# TMS320F280049 register map
Vendor: Texas Instruments; Series: C2000 F28004x; File version: 0.2.0-generated
Registers are 16-bit, read-write, reset 0x0 unless marked. A register's access mark holds for its fields unless they carry their own. Offsets are from the block's base; [hi:lo] are bit positions; {n}, {i} and the like mark numbered series.

## OUTPUTXBARREGS — OUTPUT XBAR Registers
Base 0x0000F500
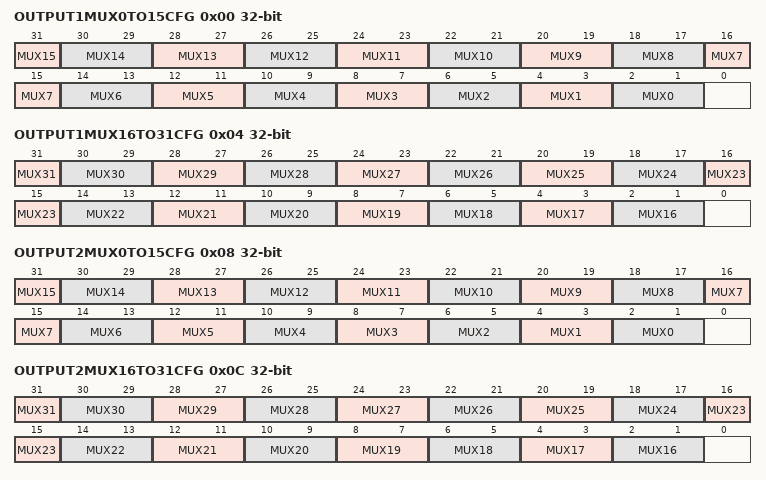
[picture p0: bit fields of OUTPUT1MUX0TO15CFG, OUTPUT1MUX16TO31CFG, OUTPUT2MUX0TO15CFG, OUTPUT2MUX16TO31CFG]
0x00 OUTPUT1MUX0TO15CFG 32-bit — Output X-BAR Mux Configuration for Output 1
  [31] MUX15 — Mux15 Configuration for OUTPUT1 of OUTPUT-XBAR
  [2n+2:2n+1] MUX{n} (n=0..14) — Mux{n} Configuration for OUTPUT1 of OUTPUT-XBAR
0x04 OUTPUT1MUX16TO31CFG 32-bit — Output X-BAR Mux Configuration for Output 1
  [31] MUX31 — Mux31 Configuration for OUTPUT1 of OUTPUT-XBAR
  [2n-30:2n-31] MUX{n} (n=16..30) — Mux{n} Configuration for OUTPUT1 of OUTPUT-XBAR
0x08 OUTPUT2MUX0TO15CFG 32-bit — Output X-BAR Mux Configuration for Output 2
  [31] MUX15 — Mux15 Configuration for OUTPUT2 of OUTPUT-XBAR
  [2n+2:2n+1] MUX{n} (n=0..14) — Mux{n} Configuration for OUTPUT2 of OUTPUT-XBAR
0x0C OUTPUT2MUX16TO31CFG 32-bit — Output X-BAR Mux Configuration for Output 2
  [31] MUX31 — Mux31 Configuration for OUTPUT2 of OUTPUT-XBAR
  [2n-30:2n-31] MUX{n} (n=16..30) — Mux{n} Configuration for OUTPUT2 of OUTPUT-XBAR
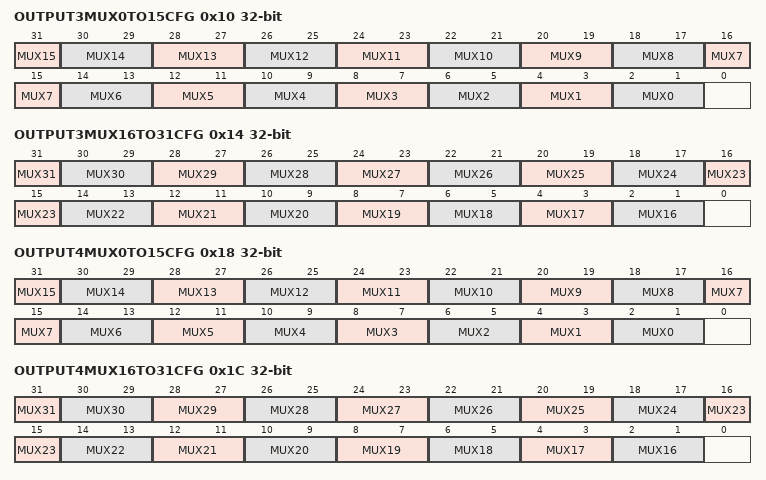
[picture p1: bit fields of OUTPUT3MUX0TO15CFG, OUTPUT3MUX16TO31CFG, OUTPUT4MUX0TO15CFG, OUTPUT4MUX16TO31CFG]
0x10 OUTPUT3MUX0TO15CFG 32-bit — Output X-BAR Mux Configuration for Output 3
  [31] MUX15 — Mux15 Configuration for OUTPUT3 of OUTPUT-XBAR
  [2n+2:2n+1] MUX{n} (n=0..14) — Mux{n} Configuration for OUTPUT3 of OUTPUT-XBAR
0x14 OUTPUT3MUX16TO31CFG 32-bit — Output X-BAR Mux Configuration for Output 3
  [31] MUX31 — Mux31 Configuration for OUTPUT3 of OUTPUT-XBAR
  [2n-30:2n-31] MUX{n} (n=16..30) — Mux{n} Configuration for OUTPUT3 of OUTPUT-XBAR
0x18 OUTPUT4MUX0TO15CFG 32-bit — Output X-BAR Mux Configuration for Output 4
  [31] MUX15 — Mux15 Configuration for OUTPUT4 of OUTPUT-XBAR
  [2n+2:2n+1] MUX{n} (n=0..14) — Mux{n} Configuration for OUTPUT4 of OUTPUT-XBAR
0x1C OUTPUT4MUX16TO31CFG 32-bit — Output X-BAR Mux Configuration for Output 4
  [31] MUX31 — Mux31 Configuration for OUTPUT4 of OUTPUT-XBAR
  [2n-30:2n-31] MUX{n} (n=16..30) — Mux{n} Configuration for OUTPUT4 of OUTPUT-XBAR
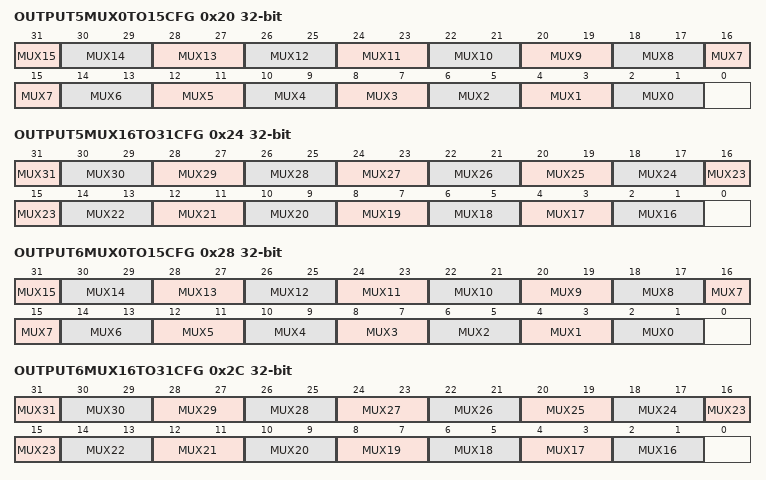
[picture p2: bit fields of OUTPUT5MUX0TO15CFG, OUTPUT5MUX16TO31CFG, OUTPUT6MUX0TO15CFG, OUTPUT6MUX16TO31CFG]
0x20 OUTPUT5MUX0TO15CFG 32-bit — Output X-BAR Mux Configuration for Output 5
  [31] MUX15 — Mux15 Configuration for OUTPUT5 of OUTPUT-XBAR
  [2n+2:2n+1] MUX{n} (n=0..14) — Mux{n} Configuration for OUTPUT5 of OUTPUT-XBAR
0x24 OUTPUT5MUX16TO31CFG 32-bit — Output X-BAR Mux Configuration for Output 5
  [31] MUX31 — Mux31 Configuration for OUTPUT5 of OUTPUT-XBAR
  [2n-30:2n-31] MUX{n} (n=16..30) — Mux{n} Configuration for OUTPUT5 of OUTPUT-XBAR
0x28 OUTPUT6MUX0TO15CFG 32-bit — Output X-BAR Mux Configuration for Output 6
  [31] MUX15 — Mux15 Configuration for OUTPUT6 of OUTPUT-XBAR
  [2n+2:2n+1] MUX{n} (n=0..14) — Mux{n} Configuration for OUTPUT6 of OUTPUT-XBAR
0x2C OUTPUT6MUX16TO31CFG 32-bit — Output X-BAR Mux Configuration for Output 6
  [31] MUX31 — Mux31 Configuration for OUTPUT6 of OUTPUT-XBAR
  [2n-30:2n-31] MUX{n} (n=16..30) — Mux{n} Configuration for OUTPUT6 of OUTPUT-XBAR
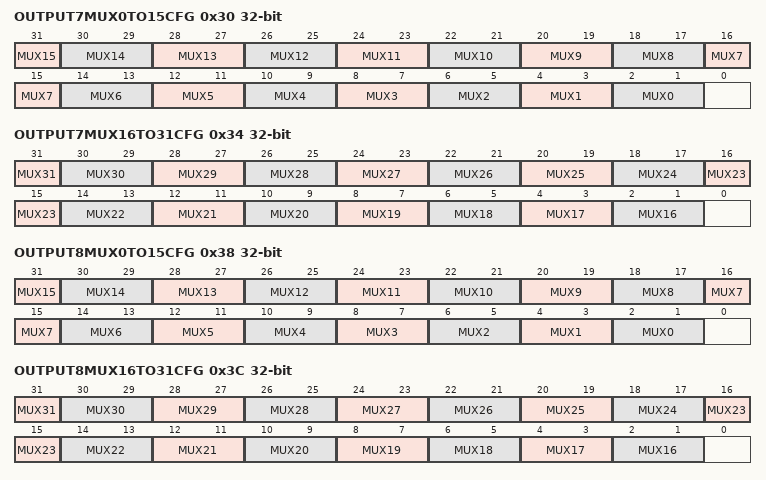
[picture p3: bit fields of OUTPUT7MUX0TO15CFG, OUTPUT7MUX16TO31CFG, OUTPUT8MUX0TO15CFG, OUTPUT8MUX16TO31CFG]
0x30 OUTPUT7MUX0TO15CFG 32-bit — Output X-BAR Mux Configuration for Output 7
  [31] MUX15 — Mux15 Configuration for OUTPUT7 of OUTPUT-XBAR
  [2n+2:2n+1] MUX{n} (n=0..14) — Mux{n} Configuration for OUTPUT7 of OUTPUT-XBAR
0x34 OUTPUT7MUX16TO31CFG 32-bit — Output X-BAR Mux Configuration for Output 7
  [31] MUX31 — Mux31 Configuration for OUTPUT7 of OUTPUT-XBAR
  [2n-30:2n-31] MUX{n} (n=16..30) — Mux{n} Configuration for OUTPUT7 of OUTPUT-XBAR
0x38 OUTPUT8MUX0TO15CFG 32-bit — Output X-BAR Mux Configuration for Output 8
  [31] MUX15 — Mux15 Configuration for OUTPUT8 of OUTPUT-XBAR
  [2n+2:2n+1] MUX{n} (n=0..14) — Mux{n} Configuration for OUTPUT8 of OUTPUT-XBAR
0x3C OUTPUT8MUX16TO31CFG 32-bit — Output X-BAR Mux Configuration for Output 8
  [31] MUX31 — Mux31 Configuration for OUTPUT8 of OUTPUT-XBAR
  [2n-30:2n-31] MUX{n} (n=16..30) — Mux{n} Configuration for OUTPUT8 of OUTPUT-XBAR
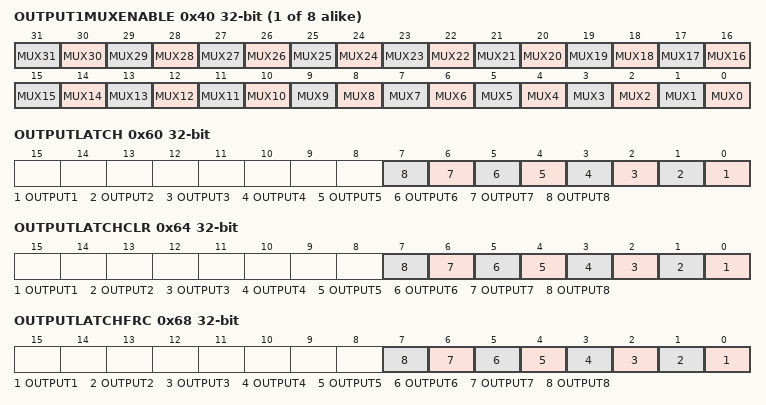
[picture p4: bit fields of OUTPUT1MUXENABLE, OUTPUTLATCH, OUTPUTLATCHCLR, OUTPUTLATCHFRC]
{0x3C+4i} OUTPUT{i}MUXENABLE 32-bit (i=1..8) — Output X-BAR Mux Enable for Output {i}
  [n] MUX{n} (n=0..31) — Mux{n} to drive OUTPUT{i} of OUTPUT-XBAR
0x60 OUTPUTLATCH 32-bit — Output X-BAR Output Latch
  [n-1] OUTPUT{n} (n=1..8) — Records the OUTPUT{n} of OUTPUT-XBAR
0x64 OUTPUTLATCHCLR 32-bit — Output X-BAR Output Latch Clear
  [n-1] OUTPUT{n} (n=1..8) — Clears the Output-Latch for OUTPUT{n} of OUTPUT-XBAR
0x68 OUTPUTLATCHFRC 32-bit — Output X-BAR Output Latch Clear
  [n-1] OUTPUT{n} (n=1..8) — Sets the Output-Latch for OUTPUT{n} of OUTPUT-XBAR
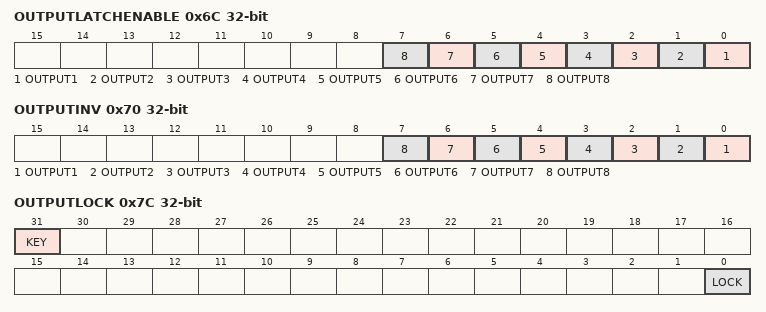
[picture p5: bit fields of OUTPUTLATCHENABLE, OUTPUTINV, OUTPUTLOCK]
0x6C OUTPUTLATCHENABLE 32-bit — Output X-BAR Output Latch Enable
  [n-1] OUTPUT{n} (n=1..8) — Selects the output latch to drive OUTPUT{n} for OUTPUT-XBAR
0x70 OUTPUTINV 32-bit — Output X-BAR Output Inversion
  [n-1] OUTPUT{n} (n=1..8) — Selects polarity for OUTPUT{n} of OUTPUT-XBAR
0x7C OUTPUTLOCK 32-bit — Output X-BAR Configuration Lock register
  [31] KEY — Write Protection KEY
  [0] LOCK — Locks the configuration for OUTPUT-XBAR
